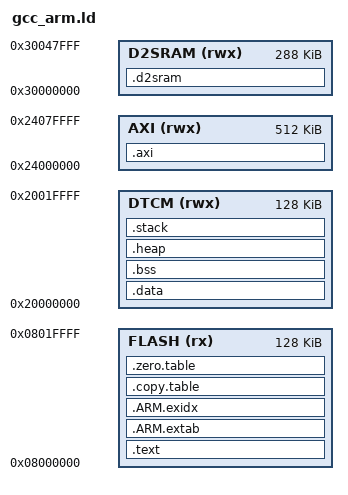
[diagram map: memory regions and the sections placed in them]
/******************************************************************************
 * @file     gcc_arm.ld
 * @brief    GNU Linker Script for Cortex-M based device
 * @version  V2.1.0
 * @date     04. August 2020
 ******************************************************************************/
/*
 * Copyright (c) 2009-2020 Arm Limited. All rights reserved.
 *
 * SPDX-License-Identifier: Apache-2.0
 *
 * Licensed under the Apache License, Version 2.0 (the License); you may
 * not use this file except in compliance with the License.
 * You may obtain a copy of the License at
 *
 * www.apache.org/licenses/LICENSE-2.0
 *
 * Unless required by applicable law or agreed to in writing, software
 * distributed under the License is distributed on an AS IS BASIS, WITHOUT
 * WARRANTIES OR CONDITIONS OF ANY KIND, either express or implied.
 * See the License for the specific language governing permissions and
 * limitations under the License.
 */

/*
 *-------- <<< Use Configuration Wizard in Context Menu >>> -------------------
 */

/*---------------------- Flash Configuration ----------------------------------
  <h> Flash Configuration
    <o0> Flash Base Address <0x0-0xFFFFFFFF:8>
    <o1> Flash Size (in Bytes) <0x0-0xFFFFFFFF:8>
  </h>
  -----------------------------------------------------------------------------*/
__ROM_BASE = 0x08000000;
__ROM_SIZE = 0x00020000;

/*--------------------- Embedded RAM Configuration ----------------------------
  <h> RAM Configuration
    <o0> RAM Base Address    <0x0-0xFFFFFFFF:8>
    <o1> RAM Size (in Bytes) <0x0-0xFFFFFFFF:8>
  </h>
 -----------------------------------------------------------------------------*/
__DTCM_BASE = 0x20000000;
__DTCM_SIZE = 0x20000;

__AXI_BASE = 0x24000000;
__AXI_SIZE = 0x80000;

__D2SRAM_BASE = 0x30000000;
__D2SRAM_SIZE = 0x48000;

/*--------------------- Stack / Heap Configuration ----------------------------
  <h> Stack / Heap Configuration
    <o0> Stack Size (in Bytes) <0x0-0xFFFFFFFF:8>
    <o1> Heap Size (in Bytes) <0x0-0xFFFFFFFF:8>
  </h>
  -----------------------------------------------------------------------------*/
__STACK_SIZE = 0x800;
__HEAP_SIZE  = 0x1000;

/*
 *-------------------- <<< end of configuration section >>> -------------------
 */

MEMORY
{
  FLASH  (rx)  : ORIGIN = __ROM_BASE, LENGTH = __ROM_SIZE
  DTCM   (rwx) : ORIGIN = __DTCM_BASE, LENGTH = __DTCM_SIZE
  AXI    (rwx) : ORIGIN = __AXI_BASE, LENGTH = __AXI_SIZE
  D2SRAM (rwx) : ORIGIN = __D2SRAM_BASE, LENGTH = __D2SRAM_SIZE
}

/* Linker script to place sections and symbol values. Should be used together
 * with other linker script that defines memory regions FLASH and RAM.
 * It references following symbols, which must be defined in code:
 *   Reset_Handler : Entry of reset handler
 *
 * It defines following symbols, which code can use without definition:
 *   __exidx_start
 *   __exidx_end
 *   __copy_table_start__
 *   __copy_table_end__
 *   __zero_table_start__
 *   __zero_table_end__
 *   __etext
 *   __data_start__
 *   __preinit_array_start
 *   __preinit_array_end
 *   __init_array_start
 *   __init_array_end
 *   __fini_array_start
 *   __fini_array_end
 *   __data_end__
 *   __bss_start__
 *   __bss_end__
 *   __end__
 *   end
 *   __HeapLimit
 *   __StackLimit
 *   __StackTop
 *   __stack
 */
ENTRY(Reset_Handler)

SECTIONS
{
  .text :
  {
    KEEP(*(.vectors))
    *(.text*)

    KEEP(*(.init))
    KEEP(*(.fini))

    /* .ctors */
    *crtbegin.o(.ctors)
    *crtbegin?.o(.ctors)
    *(EXCLUDE_FILE(*crtend?.o *crtend.o) .ctors)
    *(SORT(.ctors.*))
    *(.ctors)

    /* .dtors */
    *crtbegin.o(.dtors)
    *crtbegin?.o(.dtors)
    *(EXCLUDE_FILE(*crtend?.o *crtend.o) .dtors)
    *(SORT(.dtors.*))
    *(.dtors)

    *(.rodata*)

    KEEP(*(.eh_frame*))
  } > FLASH

  /*
   * SG veneers:
   * All SG veneers are placed in the special output section .gnu.sgstubs. Its start address
   * must be set, either with the command line option `--section-start` or in a linker script,
   * to indicate where to place these veneers in memory.
   */
/*
  .gnu.sgstubs :
  {
    . = ALIGN(32);
  } > FLASH
*/
  .ARM.extab :
  {
    *(.ARM.extab* .gnu.linkonce.armextab.*)
  } > FLASH

  __exidx_start = .;
  .ARM.exidx :
  {
    *(.ARM.exidx* .gnu.linkonce.armexidx.*)
  } > FLASH
  __exidx_end = .;

  .copy.table :
  {
    . = ALIGN(4);
    __copy_table_start__ = .;

    LONG (__etext)
    LONG (__data_start__)
    LONG ((__data_end__ - __data_start__) / 4)

    /* Add each additional data section here */
/*
    LONG (__etext2)
    LONG (__data2_start__)
    LONG ((__data2_end__ - __data2_start__) / 4)
*/
    __copy_table_end__ = .;
  } > FLASH

  .zero.table :
  {
    . = ALIGN(4);
    __zero_table_start__ = .;
    /* Add each additional bss section here */
    LONG (__bss_start__)
    LONG ((__bss_end__ - __bss_start__) / 4)
    LONG (__axi_start__)
    LONG ((__axi_end__ - __axi_start__) / 4)
    LONG (__d2sram_start__)
    LONG ((__d2sram_end__ - __d2sram_start__) / 4)
    __zero_table_end__ = .;
  } > FLASH

  /**
   * Location counter can end up 2byte aligned with narrow Thumb code but
   * __etext is assumed by startup code to be the LMA of a section in RAM
   * which must be 4byte aligned 
   */
  __etext = ALIGN (4);

  .data : AT (__etext)
  {
    __data_start__ = .;
    *(vtable)
    *(.data)
    *(.data.*)

    . = ALIGN(4);
    /* preinit data */
    PROVIDE_HIDDEN (__preinit_array_start = .);
    KEEP(*(.preinit_array))
    PROVIDE_HIDDEN (__preinit_array_end = .);

    . = ALIGN(4);
    /* init data */
    PROVIDE_HIDDEN (__init_array_start = .);
    KEEP(*(SORT(.init_array.*)))
    KEEP(*(.init_array))
    PROVIDE_HIDDEN (__init_array_end = .);

    . = ALIGN(4);
    /* finit data */
    PROVIDE_HIDDEN (__fini_array_start = .);
    KEEP(*(SORT(.fini_array.*)))
    KEEP(*(.fini_array))
    PROVIDE_HIDDEN (__fini_array_end = .);

    KEEP(*(.jcr*))
    . = ALIGN(4);
    /* All data end */
    __data_end__ = .;

  } > DTCM

  /*
   * Secondary data section, optional
   *
   * Remember to add each additional data section
   * to the .copy.table above to asure proper
   * initialization during startup.
   */

  .bss :
  {
    . = ALIGN(4);
    __bss_start__ = .;
    *(.bss)
    *(.bss.*)
    *(COMMON)
    . = ALIGN(4);
    __bss_end__ = .;
  } > DTCM AT > DTCM

  .heap (COPY) :
  {
    . = ALIGN(8);
    __end__ = .;
    PROVIDE(end = .);
    . = . + __HEAP_SIZE;
    . = ALIGN(8);
    __HeapLimit = .;
  } > DTCM

  .stack (ORIGIN(DTCM) + LENGTH(DTCM) - __STACK_SIZE) (COPY) :
  {
    . = ALIGN(8);
    __StackLimit = .;
    . = . + __STACK_SIZE;
    . = ALIGN(8);
    __StackTop = .;
  } > DTCM

  .axi (NOLOAD) :
  {
    . = ALIGN(4);
    __axi_start__ = .;
    *(.axi)
    *(.axi.*)
    . = ALIGN(4);
    __axi_end__ = .;
  } > AXI

  .d2sram (NOLOAD) :
  {
    . = ALIGN(4);
    __d2sram_start__ = .;
    *(.d2sram)
    *(.d2sram.*)
    . = ALIGN(4);
    __d2sram_end__ = .;
  } > D2SRAM

  PROVIDE(__stack = __StackTop);

  /* Check if data + heap + stack exceeds RAM limit */
  ASSERT(__StackLimit >= __HeapLimit, "region DTCM (RAM) overflowed with stack")
}
